# TC37XPD register map
Vendor: Infineon; Series: ATVMC; File version: 100
CPU: other r0p0, little endian, MPU, FPU, vendor SysTick, 4 interrupt priority bits
Registers are 32-bit, read-write, reset 0x0 unless marked. A register's access mark holds for its fields unless they carry their own. Offsets are from the block's base; [hi:lo] are bit positions; lines under a group give offsets from that group; {n}, {i} and the like mark numbered series.

## DAM0 — DAM
Base 0xF8500000
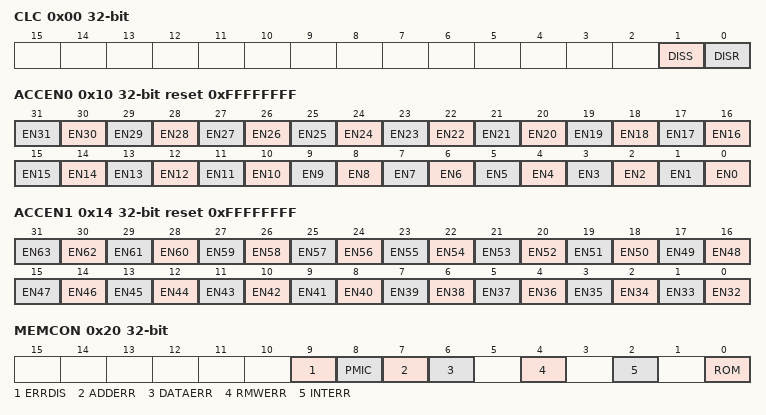
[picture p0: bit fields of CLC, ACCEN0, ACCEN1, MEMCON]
0x00 CLC access per field — DAM Clock Control Register resetvalue={Application Reset:0x0}
  [1] DISS ro — DAM Disable Status Bit DISS. Current state of DAM .
  [0] DISR rw — DAM Disable Request Bit DISR. This bit is used for enable disable control of the DAM .
0x08 MODID ro reset 0x88C003 — DAM Module ID Register resetvalue={Application Reset:0x088C003}
  [31:0] ID_VALUE — Module Identification Value ID VALUE
0x10 ACCEN0 reset 0xFFFFFFFF — DAM Access Enable Register 0 resetvalue={Application Reset:0x0FFFFFFFF}
  [n] EN{n} (n=0..31) — Access Enable for Master TAG ID 31 EN31. This bit enables access to the DAM register addresses for transactions with the Master TAG ID n
0x14 ACCEN1 reset 0xFFFFFFFF — DAM Access Enable Register 1 resetvalue={Application Reset:0x0FFFFFFFF}
  [n-32] EN{n} (n=32..63) — Access Enable for Master TAG ID 63 EN63. This bit enables access to the DAM register addresses for transactions with the Master TAG ID n
0x20 MEMCON access per field — DAM Memory Control Register resetvalue={Application Reset:0x0}
  [9] ERRDIS rw — ECC Error Disable ERRDIS. When set SRI bus errors caused by ECC errors in data read from the SRAM will be disabled
  [8] PMIC wo — Protection Bit for Memory Integrity Control Bit PMIC. Will always return 0 when read
  [7] ADDERR rw — SRI Address Phase ECC Error ADDERR. Flag set by hardware when the SRI interface detects an ECC error in the address phase of an incoming transaction. This bit is cleared by writing 0 but cannot be set by software.
  [6] DATAERR rw — SRI Data Phase ECC Error DATAERR. Flag set by hardware when the SRI interface detects an ECC error in the data phase of an incoming write transaction. This bit is cleared by writing 0 but cannot be set by software.
  [4] RMWERR rw — Internal Read Modify Write Error RMWERR. Flag set by hardware when the DAM logic detects an ECC error on the read phase of an internal RMW operation. This bit is cleared by writing 0 but cannot be set by software.
  [2] INTERR rw — Internal ECC Error INTERR. Flag set by hardware when the DAM logic detects an ECC error while accessing the RAM. This bit is cleared by writing 0 but cannot be set by software.
  [0] ROM rw — Read Only Memory ROM. Configure RAM to be Read Only Memory
{0x50+0x10*i} RGN[{i}] (i=0..7) group
  0x00 RGNLAx — DAM Region Lower Address Register resetvalue={Application Reset:0x0}
    [31:5] ADDR — Region Lower Address ADDR. Bits 31 to 5 of the SRI address which is the lower bound of the defined memory region
  0x04 RGNUAx reset 0xFFFFFFE0 — DAM Region Upper Address Register resetvalue={Application Reset:0x0FFFFFFE0}
    [31:5] ADDR — Region Lower Address ADDR. Bits 31 to 5 of the SRI address which is the upper bound of the defined memory region. i.e. the first address outside the protected region.
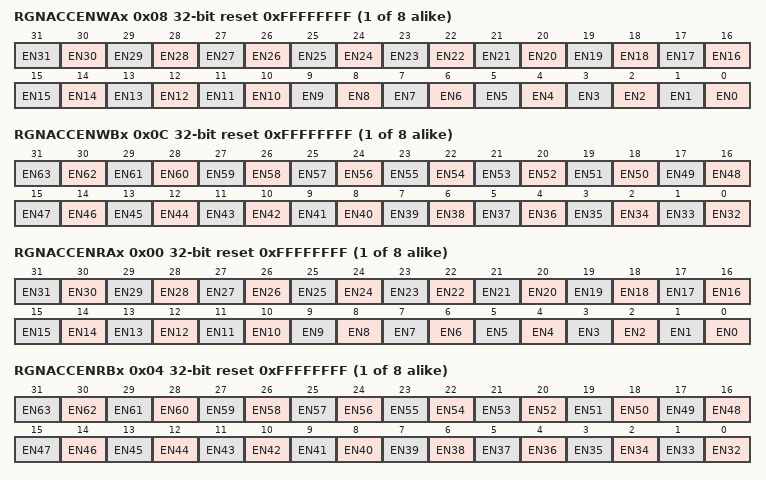
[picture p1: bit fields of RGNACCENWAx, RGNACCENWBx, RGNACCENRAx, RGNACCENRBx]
  0x08 RGNACCENWAx reset 0xFFFFFFFF — DAM Region Write Enable Register A resetvalue={Application Reset:0x0FFFFFFFF}
    [n] EN{n} (n=0..31) — Access Enable for Master TAG ID 31 EN31. This bit enables write access to the module kernel addresses for transactions with the Master TAG ID n
  0x0C RGNACCENWBx reset 0xFFFFFFFF — DAM Region Write Enable Register B resetvalue={Application Reset:0x0FFFFFFFF}
    [n-32] EN{n} (n=32..63) — Access Enable for Master TAG ID 63 EN63. This bit enables write access to the module kernel addresses for transactions with the Master TAG ID n
{0xD8+0x10*i} RGNACCEN[{i}] (i=0..7) group
  0x00 RGNACCENRAx reset 0xFFFFFFFF — DAM Region Read Enable Register A resetvalue={Application Reset:0x0FFFFFFFF}
    [n] EN{n} (n=0..31) — Access Enable for Master TAG ID 31 EN31. This bit enables read access to the module kernel addresses for transactions with the Master TAG ID n
  0x04 RGNACCENRBx reset 0xFFFFFFFF — DAM Region Read Enable Register B resetvalue={Application Reset:0x0FFFFFFFF}
    [n-32] EN{n} (n=32..63) — Access Enable for Master TAG ID 63 EN63. This bit enables read access to the module kernel addresses for transactions with the Master TAG ID n
